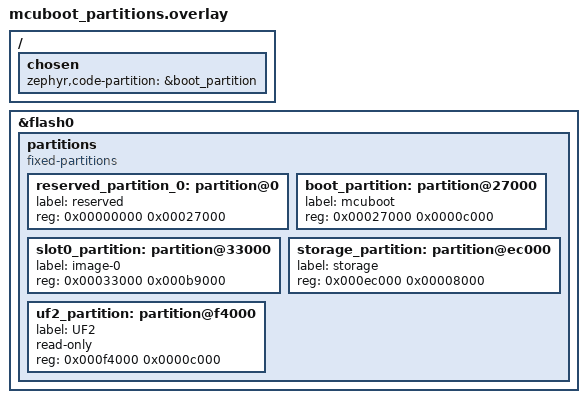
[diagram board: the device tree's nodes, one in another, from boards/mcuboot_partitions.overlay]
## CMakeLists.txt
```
#
# Copyright (c) 2025 Nordic Semiconductor ASA
#
# SPDX-License-Identifier: LicenseRef-Nordic-5-Clause
#

cmake_minimum_required(VERSION 3.20.0)

find_package(Zephyr REQUIRED HINTS $ENV{ZEPHYR_BASE})
project(beacon)

target_sources(app PRIVATE
    src/main.c
    src/bmt_auth.c
    src/bmt_beacon.c
    src/bmt_battery.c
)

# Wire protocol shared with the ESP-IDF apps (plain C header).
target_include_directories(app PRIVATE ${CMAKE_CURRENT_SOURCE_DIR}/../../components/bmt_protocol)
```

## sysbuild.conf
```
# [SECURITY] MCUboot - the Zephyr counterpart to Secure Boot V2 on ESP32 Tag.
# Single-slot mode: MCUboot only verifies the signature and boots
# slot0_partition. OTA over BLE is not supported yet (updates = re-flash
# the whole UF2 via the pre-installed Adafruit bootloader, see
# boards/xiao_ble_nrf52840.overlay for why the layout is this way).
SB_CONFIG_BOOTLOADER_MCUBOOT=y
SB_CONFIG_MCUBOOT_MODE_SINGLE_APP=y
SB_CONFIG_BOOT_SIGNATURE_TYPE_ECDSA_P256=y
SB_CONFIG_BOOT_SIGNATURE_KEY_FILE="../../keys/bmt_tag_ecdsa_p256.pem"
```

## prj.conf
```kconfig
CONFIG_BT=y
CONFIG_BT_DEVICE_NAME="Test beacon"

# PSA Crypto (HMAC-SHA256) - needed by bmt_auth for epoch key rotation.
CONFIG_PSA_CRYPTO=y
CONFIG_PSA_WANT_ALG_HMAC=y
CONFIG_PSA_WANT_ALG_SHA_256=y
CONFIG_PSA_WANT_KEY_TYPE_HMAC=y

# [POWER] Drop the radio TX power from the default 0 dBm to -4 dBm. Cuts
# current at TX (also reduces the current pulse amplitude through the
# diode / cap - see bmt_battery.c and the CR2032 sag discussion), at the
# cost of slightly shorter range - re-verify real-world distance after
# flashing.
CONFIG_BT_CTLR_TX_PWR_MINUS_4=y

# [POWER] Read the battery via the internal SAADC (VDD) - see bmt_battery.c.
CONFIG_ADC=y

# =====================================================================
# [POWER] Disable USB + CONSOLE + LOG - the largest single saving (~0.7-0.8 mA)
# =====================================================================
#
# First tried disabling USB on this board by picking off individual
# symbols (CONFIG_CONSOLE / UART_CONSOLE / SERIAL=n one at a time) and hit
# a build error: "undefined reference __device_dts_ord_125" in
# log_backend_uart.c - because CONFIG_LOG stayed on, the log backend was
# still compiled, but the UART device had been dropped from devicetree.
# Left this OFF for a while because of that error.
#
# After the ProMicro variant measured and confirmed the right switch
# (see prj.conf in Beacon_ProMicroNrf52840, ~0.7 mA of ~1.9 mA total),
# apply the same fix here: turn off BOTH
# CONFIG_BOARD_SERIAL_BACKEND_CDC_ACM AND CONFIG_LOG at the same time
# (do not split), because CONFIG_LOG=n is what drops log_backend_uart.c
# from the build and avoids the earlier undefined-reference error.
#
# DEBUG NOTE: turning these off means NO COM port and NO log. When you
# need logs, build with debug.conf to bring them back (see README, Build).
CONFIG_BOARD_SERIAL_BACKEND_CDC_ACM=n
CONFIG_LOG=n

# [POWER] APPROACH A (continuous low-power advertising):
#  - CPU auto-sleeps (System ON idle) between transmits: Zephyr's idle
#    thread handles this - no config needed.
#  - DC/DC regulator: ALREADY ENABLED via the board devicetree (reg1 =
#    DCDC mode); nRF52's soc.c reads that property and calls
#    nrf_power_dcdcen_set(true) at boot, so NO extra config here.
#    (Verified against soc/nordic/nrf52/soc.c.)
#  - 1 s interval (bmt_config.h) and TX -4 dBm already set.
# => Approach A is close to optimal by construction; real current
#    measurement needs a Power Profiler (PPK2).
```

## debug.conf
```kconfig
# =====================================================================
# DEBUG BUILD - re-enable console / log over USB CDC-ACM
# =====================================================================
#
# prj.conf (production) DISABLES USB + console + log because they draw
# ~0.7-0.8 mA continuously even after the USB cable is unplugged - 
# see the full explanation in prj.conf.
#
# This file re-enables them so you can read logs for debugging. DO NOT
# USE FOR CURRENT MEASUREMENT: the reading will be ~0.7-0.8 mA higher
# than the real firmware.
#
# Build command:
#   west build -b xiao_ble/nrf52840 -d build_debug . --pristine \
#       -- "-DBeacon_XiaoNrf52840_EXTRA_CONF_FILE=debug.conf"
#
# (The "Beacon_XiaoNrf52840_" prefix is required - this is a sysbuild
#  multi-image build; without the prefix CMake configure will fail.)

# Re-enable the switch that prj.conf turned off. This drags in the
# whole cluster: SERIAL, CONSOLE, UART_CONSOLE, USB_DEVICE_STACK_NEXT,
# CDC_ACM_SERIAL_INITIALIZE_AT_BOOT (see prj.conf for the detail).
#
# NOTE: setting only CONFIG_CONSOLE=y / SERIAL=y without this line is
# USELESS - the console comes up but there is no UART device to send
# output to, so no COM port appears. (Been caught by this once on
# ProMicro.)
CONFIG_BOARD_SERIAL_BACKEND_CDC_ACM=y
CONFIG_LOG=y

# Bump the USB buffer pool to avoid "udc: Failed to allocate net_buf N"
# when USB control transactions and CDC-ACM log traffic overlap (after
# SUSPEND / RESUME).
CONFIG_UDC_BUF_POOL_SIZE=4096
CONFIG_UDC_BUF_COUNT=32
```

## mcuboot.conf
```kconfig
# [SECURITY] MCUboot on nRF52840 boards uses USB CDC-ACM as its default
# console (the board has no dedicated debug UART), but MCUboot does NOT
# enable the USB stack (minimal bootloader, does not need it). Result:
# missing driver link -> "undefined reference to __device_dts_ord_N".
# MCUboot has nothing useful to print anyway (only verifies signature
# and jumps to slot0_partition), so disabling the console is the
# simplest fix - and reduces attack surface (no version / debug info
# leaked over serial).
CONFIG_UART_CONSOLE=n
CONFIG_CONSOLE=n
```

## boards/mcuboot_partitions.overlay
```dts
/*
 * [SECURITY] Partition copy of xiao_ble_nrf52840.overlay, dedicated
 * to MCUboot's own build (not the "beacon" app).
 *
 * WHY A SEPARATE FILE: Zephyr auto-applies boards/xiao_ble_nrf52840.overlay
 * only to the main app (beacon). MCUboot is a COMPLETELY SEPARATE
 * Zephyr app that sysbuild builds in its own directory
 * (bootloader/mcuboot/boot/zephyr), so the overlay must be passed
 * explicitly via mcuboot_EXTRA_DTC_OVERLAY_FILE (see
 * sysbuild/CMakeLists.txt).
 *
 * DO NOT share a file with the app: "chosen { zephyr,code-partition }"
 * must DIFFER between the two - MCUboot must link into boot_partition
 * (0x27000) while the app must link into slot0_partition (0x33000).
 * Sharing (a single chosen line) would make MCUboot link into
 * slot0_partition and overwrite the app itself - this actually
 * happened during a test build (0x33000 collision between the two
 * .hex files).
 */

/delete-node/ &reserved_partition_0;
/delete-node/ &code_partition;
/delete-node/ &storage_partition;
/delete-node/ &boot_partition;

/ {
	chosen {
		zephyr,code-partition = &boot_partition;
	};
};

&flash0 {
	partitions {
		compatible = "fixed-partitions";
		#address-cells = <1>;
		#size-cells = <1>;

		reserved_partition_0: partition@0 {
			label = "reserved";
			reg = <0x00000000 0x00027000>;
		};

		boot_partition: partition@27000 {
			label = "mcuboot";
			reg = <0x00027000 0x0000c000>;
		};

		slot0_partition: partition@33000 {
			label = "image-0";
			reg = <0x00033000 0x000b9000>;
		};

		storage_partition: partition@ec000 {
			label = "storage";
			reg = <0x000ec000 0x00008000>;
		};

		uf2_partition: partition@f4000 {
			label = "UF2";
			read-only;
			reg = <0x000f4000 0x0000c000>;
		};
	};
};
```

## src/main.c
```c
#include <zephyr/kernel.h>
#include <zephyr/sys/printk.h>
#include <zephyr/logging/log.h>

#include <zephyr/bluetooth/bluetooth.h>

#include "bmt_auth.h"
#include "bmt_beacon.h"
#include "bmt_battery.h"

LOG_MODULE_REGISTER(bmt_main, LOG_LEVEL_INF);

static void bt_ready(int err)
{
	if (err)
	{
		LOG_ERR("Bluetooth init failed (err %d)", err);
		return;
	}
	LOG_INF("Bluetooth initialized");

	/* MUST be called before bmt_beacon_start() - the beacon needs
	 * the HMAC key ready so it can compute mac16 for the very
	 * first ADV. */
	bmt_auth_init();

	err = bmt_beacon_start();
	if (err)
	{
		LOG_ERR("bmt_beacon_start failed (err %d)", err);
		return;
	}
	LOG_INF("BMT Tag beacon started");
}

int main(void)
{
	printk("=== BMT Tag (nRF52840) starting ===\n");

	/* Battery reading has nothing to do with BLE, start it in
	 * parallel with bt_enable. */
	int batt_err = bmt_battery_init();
	if (batt_err)
	{
		LOG_ERR("bmt_battery_init failed (err %d)", batt_err);
	}

	int err = bt_enable(bt_ready);
	if (err)
	{
		LOG_ERR("bt_enable failed (err %d)", err);
	}
	return 0;
}
```

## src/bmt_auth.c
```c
#include "bmt_auth.h"

#include <inttypes.h>

#include <zephyr/kernel.h>
#include <zephyr/logging/log.h>
#include "psa/crypto.h"

LOG_MODULE_REGISTER(bmt_auth, LOG_LEVEL_INF);

/* [SECURITY] Master key - NOT used directly to sign the payload. It
 * derives a separate key per epoch (rotated over time, TOTP-style,
 * receiver-less: Tag has no mesh / WiFi, so it cannot receive a
 * pushed rotation like the OTA-beacon key does on Scanner). If this
 * key is stolen from flash, the attacker still has to recompute the
 * current epoch key - they cannot "replay a single static key
 * forever".
 * MUST match BMT_TAG_MASTER_KEY on the ESP32 Tag byte-for-byte. */
static const uint8_t BMT_TAG_MASTER_KEY[16] = {
    0x76, 0x9F, 0xD5, 0x0D, 0xDF, 0x25, 0xA7, 0x7B,
    0x12, 0x7F, 0xDB, 0xC0, 0xCB, 0xFF, 0xF8, 0xB1};

/* Epoch tick = 1 h. Tag has no RTC / WiFi, so the epoch is a LOCAL
 * counter measured from boot (k_uptime_get(), not wall-clock) - 
 * resets to 0 on every power loss (CR2032 swap). Scanner deals with
 * the drift via windowed resync. MUST match the value on the
 * Scanner (ESP32). */
#define BMT_EPOCH_TICK_SEC 3600

static psa_key_id_t s_master_key_id = 0;
static psa_key_id_t s_epoch_key_id = 0;
static uint16_t s_cached_epoch = 0xFFFF; /* invalid value -> forces derivation on first use */

static uint16_t current_epoch(void)
{
	/* k_uptime_get() returns milliseconds (int64_t) since boot - 
	 * different from ESP-IDF's esp_timer_get_time() which is
	 * microseconds. Adjust the scale factor accordingly. */
	return (uint16_t)(k_uptime_get() / (1000LL * BMT_EPOCH_TICK_SEC));
}

static void ensure_epoch_key(uint16_t epoch)
{
	if (epoch == s_cached_epoch && s_epoch_key_id != 0)
		return;

	uint8_t derived[32];
	size_t derived_len = 0;
	uint8_t epoch_le[2] = {(uint8_t)(epoch & 0xFF), (uint8_t)(epoch >> 8)};

	psa_status_t st = psa_mac_compute(s_master_key_id, PSA_ALG_HMAC(PSA_ALG_SHA_256),
	                                  epoch_le, sizeof(epoch_le), derived, sizeof(derived), &derived_len);
	if (st != PSA_SUCCESS)
	{
		LOG_ERR("derive epoch key failed: %d", (int)st);
		return;
	}

	if (s_epoch_key_id != 0)
		psa_destroy_key(s_epoch_key_id);

	psa_key_attributes_t attr = PSA_KEY_ATTRIBUTES_INIT;
	psa_set_key_usage_flags(&attr, PSA_KEY_USAGE_SIGN_MESSAGE);
	psa_set_key_algorithm(&attr, PSA_ALG_HMAC(PSA_ALG_SHA_256));
	psa_set_key_type(&attr, PSA_KEY_TYPE_HMAC);
	psa_set_key_bits(&attr, 128);

	st = psa_import_key(&attr, derived, 16, &s_epoch_key_id);
	if (st != PSA_SUCCESS)
	{
		LOG_ERR("import epoch key failed: %d", (int)st);
		s_epoch_key_id = 0;
		return;
	}
	s_cached_epoch = epoch;
	LOG_INF("[SECURITY] epoch key rotated -> epoch=%u", epoch);
}

void bmt_auth_init(void)
{
	psa_status_t st = psa_crypto_init();
	if (st != PSA_SUCCESS)
	{
		LOG_ERR("psa_crypto_init failed: %d", (int)st);
		return;
	}

	psa_key_attributes_t attr = PSA_KEY_ATTRIBUTES_INIT;
	psa_set_key_usage_flags(&attr, PSA_KEY_USAGE_SIGN_MESSAGE);
	psa_set_key_algorithm(&attr, PSA_ALG_HMAC(PSA_ALG_SHA_256));
	psa_set_key_type(&attr, PSA_KEY_TYPE_HMAC);
	psa_set_key_bits(&attr, 8 * sizeof(BMT_TAG_MASTER_KEY));

	st = psa_import_key(&attr, BMT_TAG_MASTER_KEY, sizeof(BMT_TAG_MASTER_KEY), &s_master_key_id);
	if (st != PSA_SUCCESS)
	{
		LOG_ERR("psa_import_key failed: %d", (int)st);
		return;
	}
	ensure_epoch_key(current_epoch());
	LOG_INF("HMAC master key imported OK (key_id=%" PRIu32 ")", (uint32_t)s_master_key_id);
}

uint16_t bmt_auth_hmac16(const uint8_t* data, size_t len)
{
	ensure_epoch_key(current_epoch());

	uint8_t mac[32];
	size_t mac_len = 0;

	psa_status_t st = psa_mac_compute(s_epoch_key_id, PSA_ALG_HMAC(PSA_ALG_SHA_256),
	                                  data, len, mac, sizeof(mac), &mac_len);
	if (st != PSA_SUCCESS)
	{
		LOG_ERR("psa_mac_compute failed: %d", (int)st);
		return 0;
	}
	return (uint16_t)((mac[0] << 8) | mac[1]);
}
```

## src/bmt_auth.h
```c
#pragma once

#include <stddef.h>
#include <stdint.h>

/* Call once at boot, BEFORE the first build_adv_data(). */
void bmt_auth_init(void);

/* Compute HMAC-16 over the payload - used when building an ADV frame
 * on each sequence bump. */
uint16_t bmt_auth_hmac16(const uint8_t* data, size_t len);
```

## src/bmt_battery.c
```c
#include "bmt_battery.h"

#include <zephyr/kernel.h>
#include <zephyr/device.h>
#include <zephyr/devicetree.h>
#include <zephyr/drivers/adc.h>
#include <zephyr/drivers/gpio.h>
#include <zephyr/logging/log.h>

LOG_MODULE_REGISTER(bmt_battery, LOG_LEVEL_INF);

/* [POWER] Read the battery over the BAT+ / BAT- rail (LIR2032 3.6 V
 * or LiPo).
 *
 * Why NOT read VDD directly: when the cell feeds through the
 * on-board regulator, VDD is pinned at ~3.3 V regardless of whether
 * the cell is at 4.2 V or 3.4 V - so reading VDD tells us nothing
 * useful. Read the voltage at the BAT+ node through the on-board
 * 1M/510k divider brought out to P0.31 (AIN7). Formula and resistor
 * values follow the Tjoms99/xiao_sense_nrf52840_battery_lib
 * community library (verified on real hardware).
 *
 * (If later switching back to a CR2032 wired straight to 3V3,
 * change this to read NRF_SAADC_VDD in the overlay and drop the
 * divider - different supply, different measurement path.) */
static const struct adc_dt_spec battery_adc = ADC_DT_SPEC_GET_BY_IDX(DT_PATH(zephyr_user), 0);

/* On-board divider: BAT+ --[R1]-- P0.31 --[R2]-- (P0.14 pulls GND).
 * V_bat = V_adc * (R1 + R2) / R2. Nominal 1M / 510k; R1 is set to
 * 1037k per the empirical calibration from the reference library
 * (resistor tolerance). For higher accuracy, measure real V_bat
 * with a DMM and recompute R1. */
#define BMT_BATT_R1_KOHM 1037
#define BMT_BATT_R2_KOHM 510

/* P0.14 = VBAT_ENABLE (active-low): drive LOW to close the divider
 * into the measurement path.
 * P0.17 = charge status (LOW while charging). */
static const struct device* gpio0 = DEVICE_DT_GET(DT_NODELABEL(gpio0));
#define BMT_BATT_ENABLE_PIN 14
#define BMT_BATT_CHARGE_STAT_PIN 17

/* Voltage -> percent lookup for Li-ion (LIR2032 / LiPo). The Li-ion
 * SoC-vs-voltage curve is strongly non-linear, so a single linear
 * formula would be wrong across the range - use a table and
 * interpolate between adjacent points. 4200 mV = 100% (full),
 * 3300 mV = 0% (safe cutoff; below this the cell degrades).
 * Curve from the Tjoms99 library and the Nordic SoC blog. */
typedef struct
{
	uint16_t mv;
	uint8_t pct;
} batt_point_t;

static const batt_point_t BATT_CURVE[] = {
    {4200, 100},
    {4110, 90},
    {4020, 80},
    {3930, 70},
    {3840, 60},
    {3750, 50},
    {3660, 40},
    {3570, 30},
    {3480, 20},
    {3390, 10},
    {3300, 0},
};
#define BATT_CURVE_N (sizeof(BATT_CURVE) / sizeof(BATT_CURVE[0]))

#define BMT_BATT_LOG_INTERVAL_SEC 30

static struct k_timer batt_log_timer;
static struct k_work batt_log_work;

/* Cached % - the beacon reads this and embeds it in each ADV
 * (instead of hitting the ADC per packet). Refreshed by the work
 * handler (30 s) and once synchronously during init. */
static uint8_t s_last_percent = 0;

uint8_t bmt_battery_last_percent(void)
{
	return s_last_percent;
}

int bmt_battery_read_mv(void)
{
	int16_t raw = 0;
	struct adc_sequence sequence = {
	    .buffer = &raw,
	    .buffer_size = sizeof(raw),
	};

	int err = adc_sequence_init_dt(&battery_adc, &sequence);
	if (err < 0)
	{
		LOG_ERR("adc_sequence_init_dt failed (%d)", err);
		return err;
	}

	err = adc_read_dt(&battery_adc, &sequence);
	if (err < 0)
	{
		LOG_ERR("adc_read_dt failed (%d)", err);
		return err;
	}

	int32_t adc_mv = raw;
	err = adc_raw_to_millivolts_dt(&battery_adc, &adc_mv);
	if (err < 0)
	{
		LOG_ERR("adc_raw_to_millivolts_dt failed (%d)", err);
		return err;
	}

	/* Reverse the divider ratio to recover the real BAT+ voltage. */
	int32_t vbat = (adc_mv * (BMT_BATT_R1_KOHM + BMT_BATT_R2_KOHM)) / BMT_BATT_R2_KOHM;
	return vbat;
}

uint8_t bmt_battery_percent(int mv)
{
	if (mv >= BATT_CURVE[0].mv)
		return 100;
	if (mv <= BATT_CURVE[BATT_CURVE_N - 1].mv)
		return 0;

	for (size_t i = 0; i < BATT_CURVE_N - 1; i++)
	{
		uint16_t hi = BATT_CURVE[i].mv;
		uint16_t lo = BATT_CURVE[i + 1].mv;
		if (mv <= hi && mv >= lo)
		{
			/* Linear interpolation between the two adjacent points. */
			int pct_hi = BATT_CURVE[i].pct;
			int pct_lo = BATT_CURVE[i + 1].pct;
			return (uint8_t)(pct_lo + ((mv - lo) * (pct_hi - pct_lo)) / (hi - lo));
		}
	}
	return 0;
}

bool bmt_battery_is_charging(void)
{
	/* P0.17 LOW = charging (charger IC pulls it down). */
	return gpio_pin_get(gpio0, BMT_BATT_CHARGE_STAT_PIN) == 0;
}

static void batt_log_work_handler(struct k_work* work)
{
	ARG_UNUSED(work);

	int mv = bmt_battery_read_mv();
	if (mv < 0)
	{
		LOG_ERR("Battery read failed (%d)", mv);
		return;
	}
	s_last_percent = bmt_battery_percent(mv);
	LOG_INF("[BATTERY] BAT+=%d mV (~%u%%) %s", mv, s_last_percent,
	        bmt_battery_is_charging() ? "[CHARGING]" : "");
}

static void batt_log_timer_handler(struct k_timer* timer)
{
	/* k_timer callback runs in ISR context; adc_read may block,
	 * so hand it off to the workqueue. */
	ARG_UNUSED(timer);
	k_work_submit(&batt_log_work);
}

int bmt_battery_init(void)
{
	if (!device_is_ready(gpio0))
	{
		LOG_ERR("gpio0 not ready");
		return -ENODEV;
	}

	/* P0.14 VBAT_ENABLE active-low: OUTPUT_ACTIVE -> drive LOW ->
	 * close the divider into the measurement path. Keep LOW for
	 * the whole lifetime (see the overlay note) - MUST NOT be
	 * HIGH (even briefly): Seeed officially warns that P0.31 can
	 * overshoot the ADC input limit when P0.14 is HIGH. */
	int err = gpio_pin_configure(gpio0, BMT_BATT_ENABLE_PIN,
	                             GPIO_OUTPUT_ACTIVE | GPIO_ACTIVE_LOW);
	if (err < 0)
	{
		LOG_ERR("config VBAT_ENABLE (P0.14) failed (%d)", err);
		return err;
	}

	/* P0.17 charge-status: INPUT to read the charge state. */
	err = gpio_pin_configure(gpio0, BMT_BATT_CHARGE_STAT_PIN, GPIO_INPUT);
	if (err < 0)
	{
		LOG_ERR("config CHARGE_STAT (P0.17) failed (%d)", err);
		return err;
	}

	if (!adc_is_ready_dt(&battery_adc))
	{
		LOG_ERR("ADC device %s not ready", battery_adc.dev->name);
		return -ENODEV;
	}

	err = adc_channel_setup_dt(&battery_adc);
	if (err < 0)
	{
		LOG_ERR("adc_channel_setup_dt failed (%d)", err);
		return err;
	}

	LOG_INF("Battery ADC (BAT+ on-board divider) ready");

	/* Synchronous read once so s_last_percent has a valid value
	 * BEFORE the beacon starts advertising (build_adv_data reads
	 * bmt_battery_last_percent). */
	int mv0 = bmt_battery_read_mv();
	if (mv0 >= 0)
		s_last_percent = bmt_battery_percent(mv0);

	k_work_init(&batt_log_work, batt_log_work_handler);
	k_timer_init(&batt_log_timer, batt_log_timer_handler, NULL);
	k_timer_start(&batt_log_timer, K_SECONDS(BMT_BATT_LOG_INTERVAL_SEC),
	              K_SECONDS(BMT_BATT_LOG_INTERVAL_SEC));

	/* Print once at boot as well. */
	k_work_submit(&batt_log_work);

	return 0;
}
```

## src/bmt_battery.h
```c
#pragma once

#include <stdbool.h>
#include <stdint.h>

/* Initialise the on-board battery-measurement path (P0.14 enable
 * + P0.31 ADC via the on-board voltage divider) for a cell wired
 * to BAT+ / BAT- (LIR2032 / LiPo). See bmt_battery.c for details. */
int bmt_battery_init(void);

/* Read the actual battery voltage at BAT+ (compensating for the
 * divider ratio), in mV. Returns < 0 on error. */
int bmt_battery_read_mv(void);

/* Estimate remaining battery percentage from voltage using a Li-ion
 * lookup curve (interpolated, see BATT_CURVE in bmt_battery.c). 0-100. */
uint8_t bmt_battery_percent(int mv);

/* true when the charger IC is charging (P0.17 LOW). */
bool bmt_battery_is_charging(void);

/* Cached % from the most recent periodic read - used by the beacon
 * to embed in each ADV payload without re-reading the ADC. Refreshed
 * by a 30 s timer in bmt_battery.c and once synchronously at init. */
uint8_t bmt_battery_last_percent(void);
```

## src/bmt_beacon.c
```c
#include "bmt_beacon.h"

#include <string.h>

#include <zephyr/kernel.h>
#include <zephyr/random/random.h>
#include <zephyr/logging/log.h>

#include <zephyr/bluetooth/bluetooth.h>
#include <zephyr/bluetooth/hci.h>

#include "bmt_config.h"
#include "bmt_auth.h"
#include "bmt_types.h"
#include "bmt_battery.h"

LOG_MODULE_REGISTER(bmt_beacon, LOG_LEVEL_INF);

/* Espressif Company ID (0x02E5) - kept so existing Scanners (ESP32)
 * still recognise the tag, even though the Tag now runs a Nordic
 * chip. Scanner filters by this CID in the manufacturer data; the
 * actual chip vendor is unrelated. */
#define BMT_CID_ESPRESSIF 0x02E5

static uint8_t s_sequence = 0;
static bool s_adv_active = false;

/* Manufacturer-data buffer = 2 B CID (little-endian) + 24 B payload.
 * Backed by a static buffer (not stack) because bt_le_adv_start()
 * needs a valid data pointer at call time - same approach as
 * s_adv_raw on ESP32. */
static uint8_t s_mfg_data[2 + sizeof(bmt_tag_adv_payload_t)];

static struct k_timer s_seq_timer;
static struct k_work s_seq_work;

static void build_adv_data(void)
{
	bmt_tag_adv_payload_t p;

	memcpy(p.uuid, BMT_SYSTEM_UUID, 16);
	/* This field used to be major (PERSON / ASSET); now carries
	 * battery % (0-100). Reads the cached value (bmt_battery
	 * refreshes it every 30 s) instead of hitting the ADC on every
	 * ADV - lighter on the battery. */
	p.battery = bmt_battery_last_percent();
	p.minor = BMT_TAG_MINOR;
	p.tx_power = BMT_TAG_TX_POWER;
	p.sequence = s_sequence;
	p.mac16 = 0; /* must be 0 before computing HMAC */

	/* HMAC covers every field except the last 2 mac16 bytes - 
	 * exactly the same formula as ESP32, only the API call differs
	 * (bmt_auth_hmac16 is shared naming). */
	p.mac16 = bmt_auth_hmac16((uint8_t*)&p, sizeof(p) - sizeof(p.mac16));

	s_mfg_data[0] = (uint8_t)(BMT_CID_ESPRESSIF & 0xFF);
	s_mfg_data[1] = (uint8_t)(BMT_CID_ESPRESSIF >> 8);
	memcpy(s_mfg_data + 2, &p, sizeof(p));
}

static void start_adv_random_interval(void)
{
	/* Random [900, 1100] ms -> avoid collision with other tags,
	 * same range as ESP32. */
	uint32_t ms = BMT_ADV_INTERVAL_MIN_MS +
	              (sys_rand32_get() % (BMT_ADV_INTERVAL_MAX_MS - BMT_ADV_INTERVAL_MIN_MS + 1));

	/* One-shot: timer fires exactly after "ms" ms - in sync with
	 * the radio interval currently in use (900-1100 ms). A fixed
	 * 500 ms auto-reload timer would sit in the middle of a radio
	 * cycle and adv_stop / start incorrectly, doubling the average
	 * transmit rate. */
	k_timer_start(&s_seq_timer, K_MSEC(ms), K_NO_WAIT);

	/* BLE unit = 0.625 ms - same unit as ESP-IDF, formula identical. */
	uint16_t units = (uint16_t)((ms * 1000) / 625);

	build_adv_data();

	const struct bt_le_adv_param param = {
	    .id = BT_ID_DEFAULT,
	    .sid = 0,
	    .secondary_max_skip = 0,
	    .options = BT_LE_ADV_OPT_USE_IDENTITY, /* public address, not private / random-rotating */
	    .interval_min = units,
	    .interval_max = units,
	    .peer = NULL,
	};

	const struct bt_data ad[] = {
	    /* Flags = 0x06 (LE General Discoverable | No BR/EDR) - same
	     * hardcoded value as ESP32. */
	    BT_DATA_BYTES(BT_DATA_FLAGS, (BT_LE_AD_GENERAL | BT_LE_AD_NO_BREDR)),
	    BT_DATA(BT_DATA_MANUFACTURER_DATA, s_mfg_data, sizeof(s_mfg_data)),
	};

	int err = bt_le_adv_start(&param, ad, ARRAY_SIZE(ad), NULL, 0);
	if (err)
	{
		LOG_ERR("ADV start FAILED (err %d)", err);
		s_adv_active = false;
		return;
	}
	s_adv_active = true;
	LOG_DBG("ADV OK seq=%u batt=%u%% minor=0x%04X", s_sequence,
	        bmt_battery_last_percent(), BMT_TAG_MINOR);
}

static void seq_work_handler(struct k_work* work)
{
	ARG_UNUSED(work);
	s_sequence++; /* uint8_t: 255 -> 0 automatically, same as ESP32 */

	bt_le_adv_stop();
	start_adv_random_interval();
}

static void seq_timer_handler(struct k_timer* timer)
{
	/* [IMPORTANT] k_timer callbacks run in ISR context - must NOT
	 * call bt_le_adv_stop / start here (they can block and would
	 * fault). Dispatch the real work to the system workqueue via
	 * k_work, same principle as "FreeRTOS timer callback stays
	 * short, heavy work goes to its own task", but Zephyr enforces
	 * this stricter than ESP32 does. */
	ARG_UNUSED(timer);
	k_work_submit(&s_seq_work);
}

int bmt_beacon_start(void)
{
	k_work_init(&s_seq_work, seq_work_handler);

	/* One-shot: interval is reset inside start_adv_random_interval(). */
	k_timer_init(&s_seq_timer, seq_timer_handler, NULL);

	/* First advertise - this function calls k_timer_start() itself. */
	start_adv_random_interval();

	return 0;
}

uint8_t bmt_beacon_sequence(void)
{
	return s_sequence;
}

bool bmt_beacon_is_active(void)
{
	return s_adv_active;
}

uint16_t bmt_beacon_last_mac16(void)
{
	bmt_tag_adv_payload_t p;
	memcpy(&p, s_mfg_data + 2, sizeof(p));
	return p.mac16;
}
```

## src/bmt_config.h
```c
#pragma once

#include <stdint.h>

/* System UUID - IDENTICAL across all tags (ESP32 + nRF52840 + iPhone).
 * Scanner checks the first 4 bytes (AB 00 00 00) to recognise
 * "our system's tag". */
static const uint8_t BMT_SYSTEM_UUID[16] = {
    0xAB, 0x00, 0x00, 0x00, 0x00, 0x00, 0x00, 0x00,
    0x00, 0x00, 0x00, 0x00, 0x00, 0x00, 0x00, 0x00};
#define BMT_TAG_MINOR 0x0001   /* tag ID - change per device */
#define BMT_TAG_TX_POWER (-53) /* calibrate: measure RSSI at 1 m, then set */

/* [POWER] Random ADV interval range - avoids collisions with other
 * tags. Raised from 450-550 ms to ~900-1100 ms to reduce battery
 * drain: the radio transmits about half as often, so average current
 * drops and battery/diode sag is smaller. Scanner updates positions
 * about twice as slowly (~1 s), acceptable for a worn tag. Lower
 * again for faster localisation at the cost of battery. */
#define BMT_ADV_INTERVAL_MIN_MS 900
#define BMT_ADV_INTERVAL_MAX_MS 1100

/* Actual radio TX power is distinct from BMT_TAG_TX_POWER above (the
 * "declared" value in the payload the Scanner uses for distance
 * estimation). On Zephyr / nRF52 it is set via Kconfig
 * (CONFIG_BT_CTLR_TX_PWR_*), not a runtime API like ESP-IDF. */
```

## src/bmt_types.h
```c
#pragma once

#include <stdint.h>

/* MUST match the ESP32 struct byte-for-byte
 * (apps/tag/components/bmt_beacon/bmt_beacon.h). This is the only
 * interface between Tag and the rest of the system (Scanner / Mesh /
 * Gateway). A single-byte drift makes the Scanner refuse to recognise
 * the tag. */
#pragma pack(1)
typedef struct
{
	uint8_t uuid[16];    /* 16B: system UUID (AB000000-...) */
	uint16_t battery;    /*  2B: remaining battery % (0-100). Was "major"
	                      *      (PERSON/ASSET) - dropped because worn
	                      *      tags don't need the classification.
	                      *      Position and size kept, so HMAC and the
	                      *      24 B layout are unchanged. */
	uint16_t minor;      /*  2B: tag ID within the system */
	int8_t tx_power;     /*  1B: measured power at 1 m (calibrated) */
	uint8_t sequence;    /*  1B: 0-255, wraps -> Scanner computes loss rate */
	uint16_t mac16;      /*  2B: truncated HMAC-SHA256 (replaces CRC16) */
} bmt_tag_adv_payload_t; /* = 24 bytes */
#pragma pack()
```
